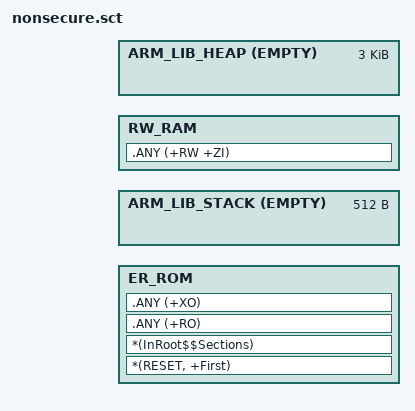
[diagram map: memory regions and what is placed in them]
#! armclang --target=arm-arm-none-eabi -march=armv8-m.main -E -xc
#define SCATTER_FILE
#include "../../partition_m3331.h"
; command above MUST be in first line (no comment above!)

/*
;-------- <<< Use Configuration Wizard in Context Menu >>> -------------------
*/

/*--------------------- Flash Configuration ----------------------------------
; <h> Flash Configuration
;   <o0> Flash Base Address <0x0-0xFFFFFFFF:8>
;   <o1> Flash Size (in Bytes) <0x0-0xFFFFFFFF:8>
; </h>
 *----------------------------------------------------------------------------*/
#define __ROM_BASE      0x00000000
#define __ROM_SIZE      0x00080000

/*--------------------- Embedded RAM Configuration ---------------------------
; <h> RAM Configuration
;   <o0> RAM Base Address    <0x0-0xFFFFFFFF:8>
;   <o1> RAM Size (in Bytes) <0x0-0xFFFFFFFF:8>
; </h>
 *----------------------------------------------------------------------------*/
#define __RAM_BASE      NON_SECURE_SRAM_BASE
#define __RAM_SIZE      SCU_SECURE_SRAM_SIZE

/*--------------------- Stack / Heap Configuration ---------------------------
; <h> Stack / Heap Configuration
;   <o0> Stack Size (in Bytes) <0x0-0xFFFFFFFF:8>
;   <o1> Heap Size (in Bytes) <0x0-0xFFFFFFFF:8>
; </h>
 *----------------------------------------------------------------------------*/
#define __STACK_SIZE    0x00000200
#define __HEAP_SIZE     0x00000C00

/*
;------------- <<< end of configuration section >>> ---------------------------
*/


/*----------------------------------------------------------------------------
  User Stack & Heap boundary definition
 *----------------------------------------------------------------------------*/
#define __STACK_TOP    (__RAM_BASE + __STACK_SIZE)   /* located at begain of RW_RAM and stackseal */
#define __HEAP_BASE    (AlignExpr(+0, 8))   /* starts after RW_RAM section, 8 byte aligned */


/*----------------------------------------------------------------------------
  Region base & size definition
 *----------------------------------------------------------------------------*/
#define __RO_BASE          ( FMC_NON_SECURE_BASE )
#define __RO_SIZE          ( FMC_SECURE_ROM_SIZE )

#define __RW_BASE          ( __STACK_TOP )
#define __RW_SIZE          ( __RAM_SIZE - __STACK_SIZE - __HEAP_SIZE )


/*----------------------------------------------------------------------------
  Scatter Region definition
 *----------------------------------------------------------------------------*/
LR_ROM __RO_BASE __RO_SIZE  {                       ; load region size_region
  ER_ROM __RO_BASE __RO_SIZE  {                     ; load address = execution address
   *(RESET, +First)
   *(InRoot$$Sections)
   .ANY (+RO)
   .ANY (+XO)
  }

  ARM_LIB_STACK (__STACK_TOP) EMPTY -(__STACK_SIZE) {   ; Reserve empty region for stack
  }

  RW_RAM __RW_BASE __RW_SIZE  {                     ; RW data
   .ANY (+RW +ZI)
  }

#if __HEAP_SIZE > 0
  ARM_LIB_HEAP  __HEAP_BASE EMPTY  __HEAP_SIZE  {   ; Reserve empty region for heap
  }
#endif
}
